# STM32U345xx register map
File version: 1.0
Registers are 32-bit, read-write, reset 0x0 unless marked. A register's access mark holds for its fields unless they carry their own. Offsets are from the block's base; [hi:lo] are bit positions.

## ADF1 — MDF/ADF
Base 0x40034000
0x00 GCR — MDF Global Control register
  [0] TRGO — Trigger output control
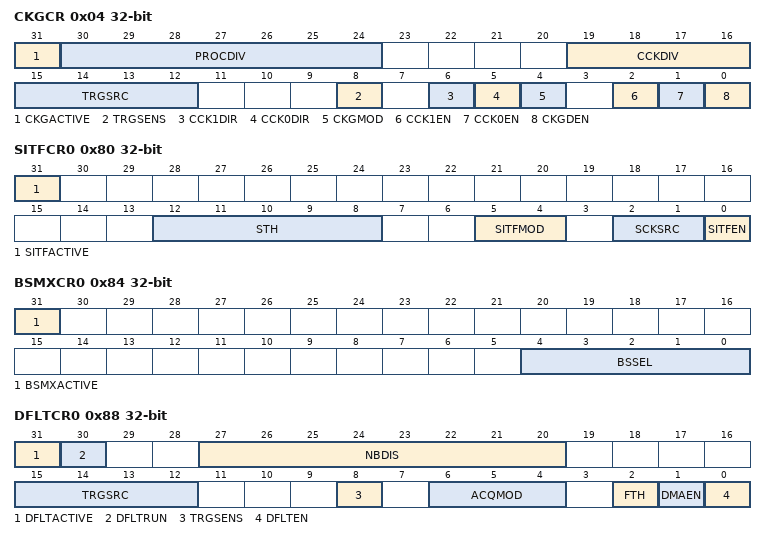
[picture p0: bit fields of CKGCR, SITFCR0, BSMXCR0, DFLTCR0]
0x04 CKGCR — MDF Clock Generator Control Register
  [31] CKGACTIVE — Clock generator active flag
  [30:24] PROCDIV — Divider to control the serial interface clock
  [19:16] CCKDIV — Divider to control the MDF_CCK clock
  [15:12] TRGSRC — Digital Filter trigger signal selection
  [8] TRGSENS — CKGEN trigger sensitivity selection
  [6] CCK1DIR — CCK1 clock direction
  [5] CCK0DIR — CCK0 clock direction
  [4] CKGMOD — Clock genartor mode
  [2] CCK1EN — CCK1 clock enable
  [1] CCK0EN — CCK0 clock enable
  [0] CKGDEN — CKGDEN dividers enable
0x20 TRGISELR — MDF Trigger Input Selection Register
  [1:0] TRGISEL — Trigger input selection
0x80 SITFCR0 — MDF Serial Interface Control Register
  [31] SITFACTIVE — Serial interface active flag
  [12:8] STH — Manchester Symbol threshold / SPI threshold
  [5:4] SITFMOD — Serial interface type
  [2:1] SCKSRC — Serial clock source
  [0] SITFEN — Serial interface enable
0x84 BSMXCR0 — MDF Bitstream Matrix Control Register
  [31] BSMXACTIVE — Bit Streal activation flag
  [4:0] BSSEL — Bit Streal selection
0x88 DFLTCR0 — MDF Digital Filter Control Register
  [31] DFLTACTIVE — Digital filter active flag
  [30] DFLTRUN — Digital filter run status flag
  [27:20] NBDIS — Number of samples to be discard
  [15:12] TRGSRC — Digital filter trigger signal selection
  [8] TRGSENS — Digital filter trigger sensitivity selection
  [6:4] ACQMOD — Digital filter trigger mode
  [2] FTH — RXFIFO Threshold selection
  [1] DMAEN — DMA request enable
  [0] DFLTEN — Digital filter enable
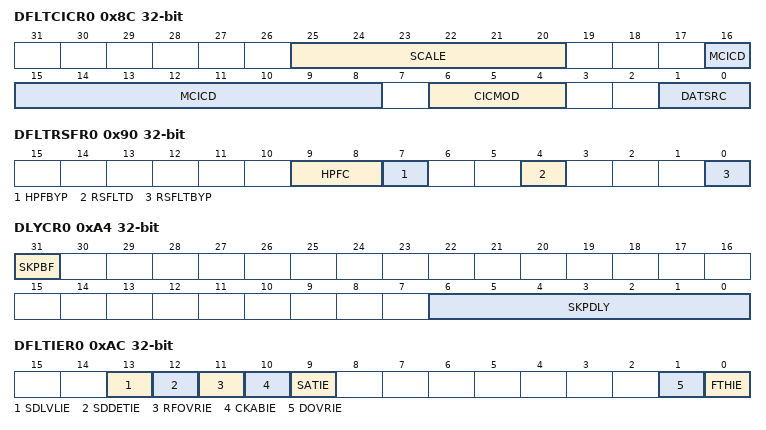
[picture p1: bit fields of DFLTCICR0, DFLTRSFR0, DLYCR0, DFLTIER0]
0x8C DFLTCICR0 — MDF MCIC Configuration Register
  [25:20] SCALE — Scaling factor selection
  [16:8] MCICD — CIC decimation ratio selection
  [6:4] CICMOD — Select the CIC Mode
  [1:0] DATSRC — Source Data for the digital filter
0x90 DFLTRSFR0 — MDF Reshape Filter Configuration Register
  [9:8] HPFC — High-pass filter cut-off frequency
  [7] HPFBYP — High-pass filter bypass
  [4] RSFLTD — Reshape filter decimation ratio
  [0] RSFLTBYP — Reshape filter bypass
0xA4 DLYCR0 — MDF Delay control Register
  [31] SKPBF — DSkip Busy Flag
  [6:0] SKPDLY — Delay to apply to a bitstream
0xAC DFLTIER0 — MDF DFLT Interrupt enable Register
  [13] SDLVLIE — Sound level value ready interrupt enable
  [12] SDDETIE — SAD interrupt enable
  [11] RFOVRIE — reshape filter overrun interrupt enable
  [10] CKABIE — Clock absence detection interrupt enable
  [9] SATIE — Saturation detection interrupt enable
  [1] DOVRIE — Data overflow interrupt enable
  [0] FTHIE — RXFIFO threshold interrupt enable
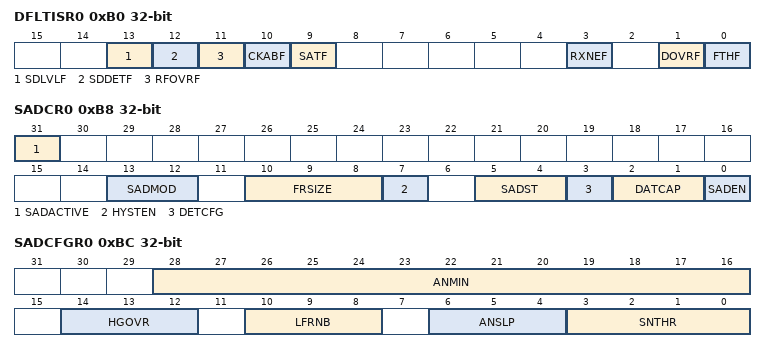
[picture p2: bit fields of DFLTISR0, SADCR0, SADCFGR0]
0xB0 DFLTISR0 — MDF DFLT Interrupt status Register
  [13] SDLVLF — Sound level value ready interrupt flag
  [12] SDDETF — SAD interrupt flag
  [11] RFOVRF — reshape filter overrun interrupt flag
  [10] CKABF — Clock absence detection interrupt flag
  [9] SATF — Saturation detection interrupt flag
  [3] RXNEF — Snapshot data ready interrupt flag
  [1] DOVRF — Data overflow interrupt flag
  [0] FTHF — RXFIFO threshold interrupt flag
0xB8 SADCR0 — MDF SAD Control Register
  [31] SADACTIVE — SAD active flag
  [13:12] SADMOD — SAD working mode
  [10:8] FRSIZE — Frame size
  [7] HYSTEN — Hysteresis enable
  [5:4] SADST — SAD state
  [3] DETCFG — SAD trigger event configuration
  [2:1] DATCAP — SAD data capture mode
  [0] SADEN — SAD enable
0xBC SADCFGR0 — MDF SAD configuration register
  [28:16] ANMIN — Hangover time window
  [14:12] HGOVR — Hangover time window
  [10:8] LFRNB — Number of learning frames
  [6:4] ANSLP — Ambiant noise slope control
  [3:0] SNTHR — Signal to noise threshold
0xC0 SADSDLVR0 — MDF SAD Sound level Register
  [14:0] SDLVL — Short term sound level
0xC4 SADANLVR0 — MDF SAD Ambient Noise level Register
  [14:0] ANLVL — Ambiant noise level estimation
0xF0 DFLTDR0 — MDF Digital Filter Data Register
  [31:8] DR — MCIC decimation counter
